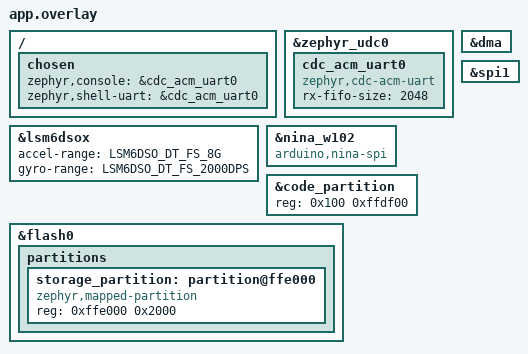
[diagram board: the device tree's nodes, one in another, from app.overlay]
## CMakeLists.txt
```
cmake_minimum_required(VERSION 3.28.0)
find_package(Zephyr REQUIRED HINTS $ENV{ZEPHYR_BASE})
project(usb_console)

target_sources(app PRIVATE src/main.c src/log_ram.c src/kv_store.c src/imu_cal.c src/imu_cal_codec.c src/wifi_profile.c
  src/time_sync.c src/time_offset.c
  src/imu_stream.c src/imu_raw_batch.c src/imu_raw_packet.c src/imu_raw_time.c
  src/imu_tick_clock.c src/imu_raw_queue.c src/imu_raw_mqtt.c src/imu_raw_status.c
  drivers/nina/nina_wifi.c drivers/nina/nina_net.c drivers/nina/nina_socket.c
  drivers/nina/nina_dns.c)
target_include_directories(app PRIVATE src drivers/lsm6dso)
# Keep Zephyr's Kconfig and devicetree bindings while using local driver copies.
function(use_local_driver_sources target pattern replacement_dir)
  get_target_property(sources ${target} SOURCES)
  set(updated_sources)
  set(replaced 0)
  foreach(source IN LISTS sources)
    if(source MATCHES "${pattern}")
      get_filename_component(filename "${source}" NAME)
      list(APPEND updated_sources "${CMAKE_CURRENT_SOURCE_DIR}/${replacement_dir}/${filename}")
      math(EXPR replaced "${replaced} + 1")
    else()
      list(APPEND updated_sources "${source}")
    endif()
  endforeach()
  if(replaced EQUAL 0)
    message(FATAL_ERROR "No sources replaced in ${target}; check the Zephyr version and configuration")
  endif()
  set_property(TARGET ${target} PROPERTY SOURCES "${updated_sources}")
endfunction()

use_local_driver_sources(drivers__i2c "(^|/)i2c_dw\\.c$" drivers/i2c_dw)
if(CONFIG_I2C_DW_RP2040_DMA)
  target_sources(drivers__i2c PRIVATE drivers/i2c_dw/i2c_dw_rp2040_commands.c)
endif()
target_include_directories(drivers__i2c PRIVATE "${ZEPHYR_BASE}/drivers/i2c")

use_local_driver_sources(drivers__sensor__st__lsm6dso "(^|/)lsm6dso(_shub|_trigger)?\\.c$" drivers/lsm6dso)
use_local_driver_sources(drivers__sensor "(^|/)sensor_shell\\.c$" drivers/sensor_shell)
target_include_directories(drivers__sensor PRIVATE ${ZEPHYR_BASE}/drivers/sensor)
target_sources(drivers__sensor__st__lsm6dso PRIVATE drivers/lsm6dso/lsm6dso_fifo.c)
target_sources(drivers__sensor__st__lsm6dso PRIVATE drivers/lsm6dso/lsm6dso_cal.c)
target_sources(drivers__sensor__st__lsm6dso PRIVATE drivers/lsm6dso/lsm6dso_zero.c)
target_sources(drivers__sensor__st__lsm6dso PRIVATE drivers/lsm6dso/lsm6dso_fifo_hw.c)
target_sources(drivers__sensor__st__lsm6dso PRIVATE drivers/lsm6dso/lsm6dso_fifo_irq.c)
if(CONFIG_SENSOR_ASYNC_API)
  target_sources(drivers__sensor__st__lsm6dso PRIVATE
    drivers/lsm6dso/lsm6dso_fifo_decoder.c
    drivers/lsm6dso/lsm6dso_compat.c
    drivers/lsm6dso/lsm6dso_stream.c)
endif()
```

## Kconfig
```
mainmenu "USB console"
source "Kconfig.zephyr"

config I2C_DW_RP2040_DMA
	bool "RP2040 I2C0 DMA reads"
	depends on SOC_RP2040 && I2C_DW && DMA_RPI_PICO && SHELL && !SMP
	depends on !I2C_DW_LPSS_DMA

config WIFI_NINA_LOCAL
	bool "NINA SPI Wi-Fi offload"
	default y
	select NET_L2_WIFI_MGMT
	select WIFI_OFFLOAD
	select NET_SOCKETS
	select NET_SOCKETS_OFFLOAD

config NINA_SPI_FREQUENCY
	int "NINA SPI frequency in Hz"
	default 8000000
	range 1000000 10000000
	depends on WIFI_NINA_LOCAL

config NINA_TCP_MAX_IO
	int "Maximum bytes per NINA TCP send"
	default 3584
	range 1 3584
	depends on WIFI_NINA_LOCAL
	help
	  Bounds each TCP send to leave room for framing in the NINA SPI
	  command buffer. A RAW batch of up to 2448 bytes plus its MQTT
	  header is sent in one command with the default.

config NINA_SEND_RETRY_MS
	int "Delay before retrying a full NINA TCP send buffer"
	default 1
	range 1 1000
	depends on WIFI_NINA_LOCAL

config NINA_NTP_SERVER
	string "NTP server hostname or IPv4 address"
	default ""
	depends on WIFI_NINA_LOCAL
	help
	  Empty uses the default gateway, normally the PC that provides the
	  Wi-Fi network and runs an NTP server for the board.

config NINA_NTP_PORT
	int "NTP server UDP port"
	default 123
	range 1 65535
	depends on WIFI_NINA_LOCAL

config NINA_NTP_INTERVAL_MS
	int "Interval between NTP queries in milliseconds"
	default 2000
	range 250 3600000
	depends on WIFI_NINA_LOCAL
	help
	  Queries go to a server on the local network. Do not point short
	  intervals at public servers.
```

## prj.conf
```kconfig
CONFIG_SERIAL=y
CONFIG_CONSOLE=y
CONFIG_UART_CONSOLE=y
CONFIG_UART_LINE_CTRL=y
CONFIG_SHELL=y
CONFIG_SHELL_HISTORY=y
CONFIG_SHELL_BACKEND_SERIAL_RX_RING_BUFFER_SIZE=2048
CONFIG_SHELL_CMD_BUFF_SIZE=512
CONFIG_SHELL_STACK_SIZE=3072
CONFIG_MAIN_STACK_SIZE=2048
CONFIG_GPIO=y
CONFIG_GPIO_SHELL=y
CONFIG_I2C=y
CONFIG_SPI=y
CONFIG_I2C_SHELL=y
CONFIG_I2C_SHELL_BUFFER_SIZE=64
CONFIG_SENSOR=y
CONFIG_SENSOR_SHELL=y
CONFIG_SENSOR_SHELL_STREAM=y
CONFIG_SENSOR_SHELL_THREAD_STACK_SIZE=3072
CONFIG_STACK_SENTINEL=y
CONFIG_POLL=y
CONFIG_LSM6DSO=y
CONFIG_REBOOT=y
# Reboot after a fatal error instead of halting; the report stays in the RAM log.
CONFIG_RESET_ON_FATAL_ERROR=y
CONFIG_THREAD_ANALYZER=y
CONFIG_THREAD_ANALYZER_USE_PRINTK=y
CONFIG_LOG=y
CONFIG_LOG_OUTPUT=y
CONFIG_LOG_TIMESTAMP_64BIT=y
CONFIG_LOG_CMDS=y
CONFIG_LOG_RUNTIME_FILTERING=y
CONFIG_SHELL_LOG_BACKEND=n
CONFIG_LOG_BACKEND_UART=n

CONFIG_USB_DEVICE_STACK_NEXT=y
CONFIG_USBD_CDC_ACM_LOG_LEVEL_OFF=y
CONFIG_CDC_ACM_SERIAL_INITIALIZE_AT_BOOT=y
CONFIG_CDC_ACM_SERIAL_PID=0x0004
CONFIG_CDC_ACM_SERIAL_PRODUCT_STRING="Zephyr USB Console"

# Measure active time from CPU idle windows, including interrupts.
CONFIG_CPU_LOAD=y
CONFIG_CPU_LOAD_BACKEND_IDLE_HOOK=y

# Use DMA for eligible I2C0 reads.
CONFIG_DMA=y
CONFIG_I2C_DW_RP2040_DMA=y

# NINA Wi-Fi management and socket offload.
CONFIG_NETWORKING=y
CONFIG_WIFI=y
CONFIG_WIFI_CREDENTIALS=y
CONFIG_WIFI_CREDENTIALS_BACKEND_SETTINGS=y
CONFIG_WIFI_NINA_LOCAL=y
CONFIG_NET_IPV4=y
CONFIG_NET_TCP=y
CONFIG_SHELL_BACKEND_TELNET=y
CONFIG_ZVFS_POLL_MAX=16
CONFIG_NET_ZPERF=y
CONFIG_NET_ZPERF_IPERF3=y
CONFIG_NET_ZPERF_SERVER=y
CONFIG_NET_L2_WIFI_SHELL=y
CONFIG_NET_SHELL=y
CONFIG_MQTT_LIB=y
# Network event callbacks may print Wi-Fi results through the shell. Measured
# peak use is 924 bytes including a Wi-Fi scan.
CONFIG_NET_MGMT_EVENT_STACK_SIZE=2048
# Every socket is offloaded to the NINA, so Zephyr's own IP stack carries no
# traffic ("net conn" stays empty). Keep its packet buffers and connection
# tables at a minimum instead of the defaults sized for native networking.
CONFIG_NET_PKT_RX_COUNT=2
CONFIG_NET_PKT_TX_COUNT=2
CONFIG_NET_BUF_RX_COUNT=4
CONFIG_NET_BUF_TX_COUNT=4
CONFIG_NET_MAX_CONTEXTS=2
CONFIG_NET_MAX_CONN=2
# Zephyr derives the size of the file descriptor table from NET_MAX_CONTEXTS,
# which no longer reflects the sockets in use. Size it for the ten NINA
# sockets, stdin/stdout/stderr and the socket service's eventfd. With too few,
# accepting a Telnet client fails in a tight loop.
CONFIG_ZVFS_OPEN_MAX=16
CONFIG_WIFI_ESP_AT=n
# Temporary non-cryptographic random generator for network testing; no TLS.
CONFIG_TEST_RANDOM_GENERATOR=y
CONFIG_NET_IPV6=n

# Persist the most recently successful Wi-Fi connection.
CONFIG_FLASH=y
CONFIG_FLASH_MAP=y
CONFIG_NVS=y
CONFIG_SETTINGS=y
CONFIG_SETTINGS_NVS=y

# Identifies the board in automatically assigned IMU session IDs.
CONFIG_HWINFO=y
```

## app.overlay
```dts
#include <zephyr/dt-bindings/sensor/lsm6dso.h>

/ {
	chosen {
		zephyr,console = &cdc_acm_uart0;
		zephyr,shell-uart = &cdc_acm_uart0;
	};
};

&zephyr_udc0 {
	cdc_acm_uart0: cdc_acm_uart0 {
		compatible = "zephyr,cdc-acm-uart";
		rx-fifo-size = <2048>;
	};
};

&dma {
	status = "okay";
};

&spi1 {
	status = "okay";
};

/* Wide ranges: the noise at 6667 Hz is well above one LSB even here, and a
 * saturated gyro sample cannot be recovered afterwards.
 */
&lsm6dsox {
	accel-range = <LSM6DSO_DT_FS_8G>;
	gyro-range = <LSM6DSO_DT_FS_2000DPS>;
};

&nina_w102 {
	compatible = "arduino,nina-spi";
};

/* Reserve the last two erase sectors for settings; keep the image separate. */
&code_partition {
	reg = <0x100 0xffdf00>;
};

&flash0 {
	partitions {
		storage_partition: partition@ffe000 {
			compatible = "zephyr,mapped-partition";
			reg = <0xffe000 0x2000>;
		};
	};
};
```

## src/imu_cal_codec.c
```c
/* SPDX-License-Identifier: Apache-2.0 */

#include <errno.h>
#include <stdio.h>
#include "imu_cal.h"

static uint32_t get_le32(const uint8_t *p)
{
	return (uint32_t)p[0] | (uint32_t)p[1] << 8 | (uint32_t)p[2] << 16 | (uint32_t)p[3] << 24;
}

int imu_cal_key(enum lsm6dso_cal_kind kind, uint32_t gain, char *key, size_t capacity)
{
	int len = snprintf(key, capacity, "imu.cal.%s.%u",
			   kind == LSM6DSO_CAL_ACCEL ? "accel" : "gyro", (unsigned int)gain);

	return len < 0 || (size_t)len >= capacity ? -ENAMETOOLONG : len;
}

int imu_cal_decode(const uint8_t *blob, size_t len, enum lsm6dso_cal_kind kind, uint32_t gain,
		   struct lsm6dso_cal *cal)
{
	if (len != IMU_CAL_BLOB_SIZE || blob[0] != IMU_CAL_VERSION || blob[2] != 0 || blob[3] != 0) {
		return -EINVAL;
	}
	if (blob[1] != (kind == LSM6DSO_CAL_ACCEL ? 0 : 1) || get_le32(blob + 4) != gain) {
		return -ENOENT;
	}
	for (int i = 0; i < 9; i++) {
		cal->m[i / 3][i % 3] = (int32_t)get_le32(blob + 8 + 4 * i);
	}
	for (int i = 0; i < 3; i++) {
		cal->bias[i] = (int32_t)get_le32(blob + 44 + 4 * i);
	}
	return 0;
}
```

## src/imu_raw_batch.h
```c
/* SPDX-License-Identifier: Apache-2.0 */
#ifndef IMU_RAW_BATCH_H_
#define IMU_RAW_BATCH_H_

#include "imu_raw_packet.h"
#include "imu_raw_time.h"

/* Runs in the FIFO consumer. The sink must not wait or retain payload; it
 * returns 0 after copying or -EAGAIN if it cannot accept the batch. */
typedef int (*imu_raw_batch_sink)(void *context, const uint8_t *payload, size_t length);
/* Optional: server (Unix) time in microseconds for a sensor tick. Called at
 * most twice per batch with ticks that never decrease. Must not wait long. */
typedef bool (*imu_raw_batch_clock)(void *context, uint64_t tick, uint64_t *unix_us);

struct imu_raw_batch {
	struct imu_raw_metadata meta;
	uint8_t payload[IMU_RAW_MAX_SIZE]; /* built in place, see imu_raw_stage_put() */
	uint64_t next_accel, next_gyro, next_batch;
	uint64_t delivered_batches, dropped_batches, dropped_accel, dropped_gyro;
	uint64_t timestamp_words;
	struct imu_raw_time time;
	size_t count, accel_count; /* words in the batch being built */
	/* A first tick was noted and awaits confirmation; see imu_raw_time.h. */
	bool accel_tick_noted, gyro_tick_noted;
	uint32_t accel_tick_generation, gyro_tick_generation;
	uint64_t accel_noted_tick, gyro_noted_tick;
	imu_raw_batch_sink sink;
	void *sink_context;
	imu_raw_batch_clock clock; /* set after init; NULL leaves Unix time invalid */
	void *clock_context;
};

/* The caller supplies a unique session ID; no random ID is generated here. */
int imu_raw_batch_init(struct imu_raw_batch *batch, const uint8_t session_id[16],
		       uint32_t epoch_id, imu_raw_batch_sink sink, void *context);
/* cursor is a byte offset into a FIFO word array. Each valid sample is
 * numbered before the sink is called. The first accelerometer and gyroscope
 * sample of a batch carry their sensor tick when imu_raw_time can assign one
 * and has confirmed it by the time the batch is flushed; otherwise the
 * time-valid flag stays clear.
 * Unsupported tags return -EPROTO without consuming the offending word.
 */
int imu_raw_batch_consume(struct imu_raw_batch *batch, const uint8_t *words,
			  size_t length, size_t *cursor);
/* Flush the incomplete batch at a deadline, stop, or before an epoch change. */
int imu_raw_batch_flush(struct imu_raw_batch *batch);
/* Call after an unknown number of samples was lost (FIFO overrun, restart,
 * unparsable word). Flushes what was collected and starts the next epoch.
 * Batch and sample numbers keep counting so they stay unique in the session;
 * consecutive numbers on both sides of an epoch change do not mean that the
 * samples are contiguous. On a flush error the epoch is left unchanged.
 */
int imu_raw_batch_new_epoch(struct imu_raw_batch *batch);
#endif
```

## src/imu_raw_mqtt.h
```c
/* SPDX-License-Identifier: Apache-2.0 */
#ifndef IMU_RAW_MQTT_H_
#define IMU_RAW_MQTT_H_
#include <stdbool.h>
#include <stddef.h>
#include <stdint.h>
#include <zephyr/net/net_ip.h>
#include "imu_raw_status.h"

/* MQTT transport for RAW batches (QoS 0), info and status. It owns a bounded
 * queue: batches are dropped and counted while disconnected or when the
 * queue is full, never retried. Thread context only. */
#define IMU_RAW_MQTT_DEVICE_ID_MAX 40

struct imu_raw_mqtt_config {
	/* 0.0.0.0 means the default gateway, looked up again for every
	 * connection attempt: the session then follows the network the board
	 * is on, and can be started before Wi-Fi is connected. */
	struct in_addr address;
	uint16_t port;
	/* Letters, digits, '-' and '_'; used in topics and the client ID. */
	char device_id[IMU_RAW_MQTT_DEVICE_ID_MAX + 1];
	uint8_t session_id[16];
};

struct imu_raw_mqtt_stats {
	bool running, connected;
	bool via_gateway;       /* no fixed address configured */
	struct in_addr address; /* of the latest connection attempt; 0 if none */
	uint16_t port;
	size_t queued, queue_high;
	uint32_t published; /* accepted by the socket, not confirmed delivered */
	uint32_t failures, connects, status_published, info_published;
	uint64_t dropped_batches, dropped_accel, dropped_gyro;
	uint64_t lock_wait_count, lock_wait_total_us, lock_wait_max_us;
	uint64_t publish_total_us, publish_max_us, publish_bytes;
};

/* -EBUSY while a previous session is still shutting down, -EINVAL for a bad
 * device ID or port. Counters restart. */
int imu_raw_mqtt_start(const struct imu_raw_mqtt_config *config);
/* Gives a final status up to half a second to leave, then disconnects. */
void imu_raw_mqtt_stop(void);
/* Sink for imu_raw_batch. May wait for the queue mutex; never waits on the
 * network. Returns -EAGAIN for a batch that was dropped. */
int imu_raw_mqtt_submit(void *context, const uint8_t *payload, size_t length);
/* Neither waits on the network. Info is published on every (re)connection and
 * when it changes; status periodically, on (re)connection and when the state
 * changes. Only the acquisition fields of *status are used. Nothing is kept
 * for a disconnected period. */
void imu_raw_mqtt_set_info(const struct imu_raw_info *info);
void imu_raw_mqtt_report(const struct imu_raw_status *status);
void imu_raw_mqtt_get_stats(struct imu_raw_mqtt_stats *stats);
#endif
```

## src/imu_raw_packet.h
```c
/* SPDX-License-Identifier: Apache-2.0 */
#ifndef IMU_RAW_PACKET_H_
#define IMU_RAW_PACKET_H_

#include <stddef.h>
#include <stdint.h>
#include "../drivers/lsm6dso/lsm6dso_fifo.h"

/* Experimental payload based on design/imu-raw-mqtt-design-ja.md §6.
 * Version 2 appends the server (Unix) time of the first sample of each kind
 * to the version 1 header:
 *   80  u64  accel_first_unix_us
 *   88  u64  gyro_first_unix_us
 * and uses flag bits 2 and 3 for their validity. Everything before offset 80
 * is laid out as in version 1.
 */
#define IMU_RAW_VERSION 2U
#define IMU_RAW_HEADER_SIZE 96U
#define IMU_RAW_MAX_WORDS 384U
#define IMU_RAW_MAX_BITMAP ((IMU_RAW_MAX_WORDS + 7U) / 8U)
#define IMU_RAW_MAX_SIZE (IMU_RAW_HEADER_SIZE + IMU_RAW_MAX_BITMAP + 6U * IMU_RAW_MAX_WORDS)
#define IMU_RAW_ACCEL_TIME_VALID 1U
#define IMU_RAW_GYRO_TIME_VALID 2U
#define IMU_RAW_ACCEL_UNIX_VALID 4U
#define IMU_RAW_GYRO_UNIX_VALID 8U
#define IMU_RAW_FLAGS_MASK 15U

struct imu_raw_metadata {
	uint8_t session_id[16];
	uint64_t batch_seq;
	uint64_t accel_first_index, gyro_first_index;
	uint64_t accel_first_tick, gyro_first_tick;
	/* Microseconds since 1970 as estimated by the board when the batch was
	 * built. Derived from the tick, so it needs the tick to be valid. */
	uint64_t accel_first_unix_us, gyro_first_unix_us;
	uint32_t epoch_id, time_map_id;
	uint8_t flags;
};

/* Encodes one complete payload. The caller owns numbering, timing, and transport.
 * An absent sensor must have index UINT64_MAX and tick 0; invalid time has tick 0
 * and an invalid Unix time is 0.
 * On error, *written is set to zero and no output bytes are changed.
 */
int imu_raw_encode(uint8_t *out, size_t capacity, size_t *written,
		   const struct imu_raw_metadata *meta,
		   const struct lsm6dso_fifo_sample *samples, size_t count);

/* The same payload built one word at a time in a buffer of IMU_RAW_MAX_SIZE
 * bytes, so that the samples need not be kept elsewhere first:
 *   imu_raw_stage_reset(), then imu_raw_stage_put() for words 0, 1, 2, ...,
 *   then imu_raw_stage_finish(), which leaves the complete payload in place.
 * `accel` is the number of accelerometer words among the `count` put.
 * After finish the buffer must be reset before the next payload, or reopened
 * with the same count to continue adding to this one. An error from finish
 * leaves the staged words untouched.
 */
void imu_raw_stage_reset(uint8_t *payload);
void imu_raw_stage_put(uint8_t *payload, size_t index, const struct lsm6dso_fifo_sample *sample);
int imu_raw_stage_finish(uint8_t *payload, size_t *written, const struct imu_raw_metadata *meta,
			 size_t count, size_t accel);
void imu_raw_stage_reopen(uint8_t *payload, size_t count);
#endif
```

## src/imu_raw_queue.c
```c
/* SPDX-License-Identifier: Apache-2.0 */
#include "imu_raw_queue.h"

#include <errno.h>
#include <string.h>

static uint16_t le16(const uint8_t *p)
{
	return (uint16_t)p[0] | ((uint16_t)p[1] << 8);
}

void imu_raw_queue_init(struct imu_raw_queue *queue)
{
	if (queue) {
		memset(queue, 0, sizeof(*queue));
	}
}

void imu_raw_queue_discard(struct imu_raw_queue *queue, const struct imu_raw_queue_item *item)
{
	if (!queue || !item) {
		return;
	}
	queue->dropped_batches++;
	queue->dropped_accel += item->accel_count;
	queue->dropped_gyro += item->gyro_count;
}

void imu_raw_queue_set_connected(struct imu_raw_queue *queue, bool connected)
{
	if (!queue) {
		return;
	}
	queue->connected = connected;
	if (!connected) {
		while (queue->count) {
			imu_raw_queue_discard(queue, &queue->items[queue->head]);
			queue->head = (queue->head + 1) % IMU_RAW_QUEUE_CAPACITY;
			queue->count--;
		}
	}
}

int imu_raw_queue_put(struct imu_raw_queue *queue, const uint8_t *payload, size_t length)
{
	struct imu_raw_queue_item *item;
	uint16_t count, bitmap, accel = 0;

	if (!queue || !payload || length < IMU_RAW_HEADER_SIZE ||
	    memcmp(payload, "IMU1", 4) || payload[4] != IMU_RAW_VERSION ||
	    le16(payload + 6) != IMU_RAW_HEADER_SIZE) {
		return -EINVAL;
	}
	count = le16(payload + 64);
	bitmap = le16(payload + 66);
	if (!count || count > IMU_RAW_MAX_WORDS || bitmap != (count + 7) / 8 ||
	    length != IMU_RAW_HEADER_SIZE + bitmap + (size_t)count * 6) {
		return -EINVAL;
	}
	for (size_t i = 0; i < count; i++) {
		accel += (payload[IMU_RAW_HEADER_SIZE + i / 8] >> (i % 8)) & 1U;
	}
	if (!queue->connected || queue->count == IMU_RAW_QUEUE_CAPACITY) {
		queue->dropped_batches++;
		queue->dropped_accel += accel;
		queue->dropped_gyro += count - accel;
		return -EAGAIN;
	}
	item = &queue->items[(queue->head + queue->count) % IMU_RAW_QUEUE_CAPACITY];
	item->length = length;
	item->accel_count = accel;
	item->gyro_count = count - accel;
	memcpy(item->payload, payload, length);
	queue->count++;
	if (queue->count > queue->high_watermark) {
		queue->high_watermark = queue->count;
	}
	return 0;
}

int imu_raw_queue_take(struct imu_raw_queue *queue, struct imu_raw_queue_item *item)
{
	if (!queue || !item) {
		return -EINVAL;
	}
	if (!queue->connected || !queue->count) {
		return -EAGAIN;
	}
	*item = queue->items[queue->head];
	queue->head = (queue->head + 1) % IMU_RAW_QUEUE_CAPACITY;
	queue->count--;
	return 0;
}
```

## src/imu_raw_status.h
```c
/* SPDX-License-Identifier: Apache-2.0 */
#ifndef IMU_RAW_STATUS_H_
#define IMU_RAW_STATUS_H_

#include <stdbool.h>
#include <stddef.h>
#include <stdint.h>

/* Experimental JSON for imu/<device_id>/status and imu/<device_id>/info
 * (design/imu-raw-mqtt-design-ja.md §5). Batch ticks are in the sensor's own
 * clock; conversion to host time is not implemented and status says so. */
enum imu_raw_state {
	IMU_RAW_STATE_IDLE,      /* session configured, no measurement yet */
	IMU_RAW_STATE_MEASURING,
	IMU_RAW_STATE_STOPPED,
};

struct imu_raw_status {
	/* Filled by the acquisition side. Numbers advance whether or not a
	 * batch was sent, so they are the reference for detecting loss. */
	uint8_t session_id[16];
	enum imu_raw_state state;
	uint32_t epoch_id;
	uint64_t uptime_ms;
	uint64_t accel_acquired, gyro_acquired, next_batch, timestamp_words;
	uint32_t fifo_overrun_observations, i2c_errors;
	int raw_error, measure_error;
	/* One reading of the sensor's tick counter and the board clock taken
	 * together, with the board's estimate of server (Unix) time for that
	 * instant. The receiver relates batch ticks to its own time from a
	 * series of these; the board does not convert sample times itself. */
	bool tick_valid, unix_valid;
	uint64_t tick;              /* extended like the batch ticks */
	int64_t tick_mono_us;       /* board clock at the middle of the read */
	uint32_t tick_window_us;    /* duration of the read */
	int64_t unix_us;            /* smoothed: strictly increasing */
	int64_t unix_estimate_us;   /* unsmoothed: may jump either way */
	uint32_t sync_delay_us;     /* round trip behind the estimate */
	/* Filled by the transport. */
	uint64_t dropped_batches, dropped_accel, dropped_gyro, published;
	uint32_t connects, failures, queue_high_watermark;
};

struct imu_raw_info {
	uint8_t session_id[16];
	uint32_t epoch_id;
	uint16_t accel_odr_hz, gyro_odr_hz; /* configured, not measured */
	uint32_t accel_ug_per_lsb, gyro_udps_per_lsb;
	uint16_t fifo_watermark;
	uint8_t timestamp_decimation;
	/* Sensor clock: one tick is 1 / (40000 * (1 + 0.0015 * freq_fine)) s per
	 * the LSM6DSO datasheet. Not related to host time. */
	int8_t freq_fine;
};

/* Both return the JSON length (without a terminator being counted) or
 * -ENOSPC/-EINVAL. The output is always NUL-terminated on success. */
int imu_raw_status_encode(char *out, size_t capacity, const struct imu_raw_status *status);
int imu_raw_info_encode(char *out, size_t capacity, const struct imu_raw_info *info,
			const char *device_id);
#endif
```

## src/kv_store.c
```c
/* SPDX-License-Identifier: Apache-2.0 */
#include <errno.h>
#include <string.h>
#include <zephyr/settings/settings.h>
#include <zephyr/shell/shell.h>
#include <zephyr/sys/util.h>
#include "kv_store.h"

#define KV_PREFIX        "app_kv/"
#define KV_SYSTEM_PREFIX "sys."

static bool shell_key_allowed(const char *key)
{
	return strncmp(key, KV_SYSTEM_PREFIX, sizeof(KV_SYSTEM_PREFIX) - 1) !=
	       0;
}

static int make_name(const char *key, char *name, size_t capacity)
{
	size_t len;

	if (!key) {
		return -EINVAL;
	}
	len = strnlen(key, KV_STORE_KEY_MAX + 1);
	if (!len || len > KV_STORE_KEY_MAX) {
		return -EINVAL;
	}
	for (size_t i = 0; i < len; i++) {
		char c = key[i];

		if (!((c >= 'a' && c <= 'z') || (c >= 'A' && c <= 'Z') ||
		      (c >= '0' && c <= '9') || c == '_' || c == '-' ||
		      c == '.')) {
			return -EINVAL;
		}
	}
	if (sizeof(KV_PREFIX) + len > capacity) {
		return -ENAMETOOLONG;
	}
	memcpy(name, KV_PREFIX, sizeof(KV_PREFIX) - 1);
	memcpy(name + sizeof(KV_PREFIX) - 1, key, len + 1);
	return 0;
}

int kv_store_init(void)
{
	return settings_subsys_init();
}

int kv_store_set(const char *key, const void *value, size_t len)
{
	char name[sizeof(KV_PREFIX) + KV_STORE_KEY_MAX];
	int ret = make_name(key, name, sizeof(name));

	if (ret) {
		return ret;
	}
	if (!value || !len || len > KV_STORE_VALUE_MAX) {
		return -EINVAL;
	}
	ret = kv_store_init();
	if (ret) {
		return ret;
	}
	return settings_save_one(name, value, len);
}

ssize_t kv_store_get(const char *key, void *value, size_t capacity)
{
	char name[sizeof(KV_PREFIX) + KV_STORE_KEY_MAX];
	ssize_t len;
	int ret = make_name(key, name, sizeof(name));

	if (ret) {
		return ret;
	}
	if (!value || !capacity) {
		return -EINVAL;
	}
	ret = kv_store_init();
	if (ret) {
		return ret;
	}
	len = settings_load_one(name, value, capacity);
	if (len == 0) {
		return -ENOENT;
	}
	if (len > 0 && (size_t)len > capacity) {
		return -ENOBUFS;
	}
	return len;
}

int kv_store_delete(const char *key)
{
	char name[sizeof(KV_PREFIX) + KV_STORE_KEY_MAX];
	int ret = make_name(key, name, sizeof(name));

	if (ret) {
		return ret;
	}
	ret = kv_store_init();
	return ret ? ret : settings_delete(name);
}

static int cmd_set(const struct shell *sh, size_t argc, char **argv)
{
	int ret;

	ARG_UNUSED(argc);
	if (!shell_key_allowed(argv[1])) {
		shell_error(sh, "Reserved key");
		return -EACCES;
	}
	ret = kv_store_set(argv[1], argv[2], strlen(argv[2]));
	if (ret) {
		shell_error(sh, "KV write failed: %d", ret);
	} else {
		shell_print(sh, "Saved");
	}
	return ret;
}

static int cmd_sethex(const struct shell *sh, size_t argc, char **argv)
{
	uint8_t value[KV_STORE_VALUE_MAX];
	size_t chars = strlen(argv[2]);
	size_t len;
	int ret;

	ARG_UNUSED(argc);
	if (!shell_key_allowed(argv[1])) {
		shell_error(sh, "Reserved key");
		return -EACCES;
	}
	if (!chars || chars % 2 || chars > sizeof(value) * 2) {
		shell_error(sh, "Expected 1-128 bytes as hexadecimal pairs");
		return -EINVAL;
	}
	len = hex2bin(argv[2], chars, value, sizeof(value));
	if (len != chars / 2) {
		shell_error(sh, "Invalid hexadecimal value");
		return -EINVAL;
	}
	ret = kv_store_set(argv[1], value, len);
	if (ret) {
		shell_error(sh, "KV write failed: %d", ret);
	} else {
		shell_print(sh, "Saved");
	}
	return ret;
}

static int cmd_get(const struct shell *sh, size_t argc, char **argv)
{
	uint8_t value[KV_STORE_VALUE_MAX];
	char hex[2 * KV_STORE_VALUE_MAX + 1];
	ssize_t len;

	ARG_UNUSED(argc);
	if (!shell_key_allowed(argv[1])) {
		shell_error(sh, "Reserved key");
		return -EACCES;
	}
	len = kv_store_get(argv[1], value, sizeof(value));
	if (len < 0) {
		shell_error(sh, "KV read failed: %d", (int)len);
		return (int)len;
	}
	bin2hex(value, len, hex, sizeof(hex));
	shell_print(sh, "%s", hex);
	return 0;
}

static int cmd_delete(const struct shell *sh, size_t argc, char **argv)
{
	int ret;

	ARG_UNUSED(argc);
	if (!shell_key_allowed(argv[1])) {
		shell_error(sh, "Reserved key");
		return -EACCES;
	}
	ret = kv_store_delete(argv[1]);
	if (ret) {
		shell_error(sh, "KV delete failed: %d", ret);
	} else {
		shell_print(sh, "Deleted");
	}
	return ret;
}

SHELL_STATIC_SUBCMD_SET_CREATE(
	kv_commands,
	SHELL_CMD_ARG(set, NULL, "Store a text value: <key> <value>", cmd_set,
		      3, 0),
	SHELL_CMD_ARG(sethex, NULL, "Store hex bytes: <key> <hex>", cmd_sethex,
		      3, 0),
	SHELL_CMD_ARG(get, NULL, "Print a value as hex: <key>", cmd_get, 2, 0),
	SHELL_CMD_ARG(delete, NULL, "Delete a value: <key>", cmd_delete, 2, 0),
	SHELL_SUBCMD_SET_END);
SHELL_CMD_REGISTER(kv, &kv_commands, "Application key-value storage", NULL);
```

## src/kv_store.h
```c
/* SPDX-License-Identifier: Apache-2.0 */
#ifndef APP_KV_STORE_H_
#define APP_KV_STORE_H_

#include <stddef.h>
#include <sys/types.h>

#define KV_STORE_KEY_MAX   32
#define KV_STORE_VALUE_MAX 128

/* Keys contain ASCII letters, digits, '.', '-' or '_'. Values are binary.
 * A zero-length value is not supported. Data is stored without encryption.
 * All calls must run in thread context and return negative errno on failure.
 */
int kv_store_init(void);
int kv_store_set(const char *key, const void *value, size_t len);
/* Returns the value length; -ENOENT if absent, -ENOBUFS if too small. */
ssize_t kv_store_get(const char *key, void *value, size_t capacity);
int kv_store_delete(const char *key);

#endif
```

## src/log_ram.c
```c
#include <zephyr/kernel.h>
#include <zephyr/linker/section_tags.h>
#include <zephyr/logging/log_backend.h>
#include <zephyr/logging/log_ctrl.h>
#include <zephyr/logging/log_msg.h>
#include <zephyr/logging/log_output.h>
#include <zephyr/shell/shell.h>

#define LOG_RAM_SIZE 4096
#define LOG_RAM_MAGIC 0x4c4f4752U

struct retained_log {
	uint32_t magic;
	uint32_t magic_inverse;
	size_t start;
	size_t length;
	char buffer[LOG_RAM_SIZE];
};

/* The linker leaves this region untouched during normal startup. */
static __noinit struct retained_log retained;
/* Bytes pushed out of the buffer since boot. Protected by log_lock. */
static uint64_t dropped;
static struct k_spinlock log_lock;
static uint8_t format_buffer[128];

static int store_output(uint8_t *data, size_t length, void *ctx)
{
	k_spinlock_key_t key;

	ARG_UNUSED(ctx);
	key = k_spin_lock(&log_lock);
	for (size_t i = 0; i < length; i++) {
		if (retained.length == LOG_RAM_SIZE) {
			retained.start = (retained.start + 1) % LOG_RAM_SIZE;
			retained.length--;
			dropped++;
		}
		retained.buffer[(retained.start + retained.length) % LOG_RAM_SIZE] = data[i];
		retained.length++;
	}
	k_spin_unlock(&log_lock, key);
	return (int)length;
}

LOG_OUTPUT_DEFINE(ram_output, store_output, format_buffer, sizeof(format_buffer));

static void ram_process(const struct log_backend *const backend, union log_msg_generic *msg)
{
	ARG_UNUSED(backend);
	log_output_msg_process(&ram_output, &msg->log,
			       LOG_OUTPUT_FLAG_TIMESTAMP | LOG_OUTPUT_FLAG_FORMAT_TIMESTAMP |
			       LOG_OUTPUT_FLAG_LEVEL | LOG_OUTPUT_FLAG_CRLF_LFONLY);
}

static void ram_panic(const struct log_backend *const backend)
{
	ARG_UNUSED(backend);
}

static log_timestamp_t timestamp_us(void)
{
	return k_cyc_to_us_floor64(k_cycle_get_64());
}

static void ram_init(const struct log_backend *const backend)
{
	ARG_UNUSED(backend);
	log_set_timestamp_func(timestamp_us, 1000000U);
	if (retained.magic != LOG_RAM_MAGIC || retained.magic_inverse != ~LOG_RAM_MAGIC ||
	    retained.start >= LOG_RAM_SIZE || retained.length > LOG_RAM_SIZE) {
		retained.start = 0;
		retained.length = 0;
		retained.magic_inverse = ~LOG_RAM_MAGIC;
		retained.magic = LOG_RAM_MAGIC;
	}
}

static const struct log_backend_api ram_backend_api = {
	.process = ram_process,
	.panic = ram_panic,
	.init = ram_init,
};

LOG_BACKEND_DEFINE(ram_backend, ram_backend_api, true);

/* Prints the log in pieces so that no second copy of it is needed. `dropped`
 * numbers the bytes from boot, which keeps the position valid when new
 * messages push old ones out while printing. */
static int cmd_dmesg(const struct shell *sh, size_t argc, char **argv)
{
	char piece[97];
	uint64_t position = 0;
	bool first = true, any = false;

	ARG_UNUSED(argc);
	ARG_UNUSED(argv);
	/* Bounded in case logging keeps up with printing. */
	for (size_t printed = 0; printed < 2U * LOG_RAM_SIZE;) {
		k_spinlock_key_t key = k_spin_lock(&log_lock);
		size_t available, n;

		if (first || position < dropped) {
			position = dropped; /* start, or skip what was overwritten */
			first = false;
		}
		available = (size_t)(dropped + retained.length - position);
		n = MIN(available, sizeof(piece) - 1);
		for (size_t k = 0; k < n; k++) {
			piece[k] = retained.buffer[(retained.start + (size_t)(position - dropped) + k) %
						   LOG_RAM_SIZE];
		}
		k_spin_unlock(&log_lock, key);
		if (!n) {
			break;
		}
		piece[n] = '\0';
		shell_fprintf(sh, SHELL_NORMAL, "%s", piece);
		position += n;
		printed += n;
		any = true;
	}
	if (!any) {
		shell_print(sh, "No logs.");
	}
	return 0;
}

SHELL_CMD_REGISTER(dmesg, NULL, "Show logs stored in RAM", cmd_dmesg);
```

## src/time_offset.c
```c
/* SPDX-License-Identifier: Apache-2.0 */
#include "time_offset.h"

#include <string.h>

void time_offset_init(struct time_offset *t)
{
	memset(t, 0, sizeof(*t));
	t->min_delay_us = UINT32_MAX;
}

static const struct time_offset_sample *best(const struct time_offset *t)
{
	const struct time_offset_sample *b = NULL;

	for (unsigned int i = 0; i < t->count; i++) {
		if (!b || t->window[i].delay_us < b->delay_us) {
			b = &t->window[i];
		}
	}
	return b;
}

bool time_offset_get(const struct time_offset *t, int64_t mono_us, int64_t *server_us,
		     uint32_t *delay_us)
{
	const struct time_offset_sample *b = best(t);
	int64_t offset;

	if (!b) {
		return false;
	}
	offset = b->offset_us;
	if (t->rate_valid) {
		offset += (mono_us - b->mono_us) * t->rate_ppb / 1000000000LL;
	}
	*server_us = mono_us + offset;
	if (delay_us) {
		*delay_us = b->delay_us;
	}
	return true;
}

static void update_rate(struct time_offset *t)
{
	const struct time_offset_sample *first = &t->anchors[0];
	const struct time_offset_sample *last = &t->anchors[t->anchor_count - 1];
	int64_t span = last->mono_us - first->mono_us;
	int64_t rate;

	if (t->anchor_count < 2 || span < TIME_OFFSET_MIN_RATE_SPAN_US) {
		return;
	}
	rate = (last->offset_us - first->offset_us) * 1000000000LL / span;
	if (rate > TIME_OFFSET_MAX_RATE_PPB || rate < -TIME_OFFSET_MAX_RATE_PPB) {
		/* Not a plausible oscillator difference: a clock was stepped or
		 * the path changed. Start over from the newest point. */
		t->anchors[0] = *last;
		t->anchor_count = 1;
		t->rate_valid = false;
		return;
	}
	t->rate_ppb = rate;
	t->rate_valid = true;
}

void time_offset_add(struct time_offset *t, const struct time_offset_sample *sample)
{
	int64_t predicted;

	t->last_residual_us = time_offset_get(t, sample->mono_us, &predicted, NULL) ?
		sample->mono_us + sample->offset_us - predicted : 0;
	t->window[t->next] = *sample;
	t->next = (t->next + 1) % TIME_OFFSET_WINDOW;
	if (t->count < TIME_OFFSET_WINDOW) {
		t->count++;
	}
	t->samples++;
	t->last_delay_us = sample->delay_us;
	if (sample->delay_us < t->min_delay_us) {
		t->min_delay_us = sample->delay_us;
	}
	/* Once per full window, keep its best exchange for the rate. */
	if (++t->since_anchor == TIME_OFFSET_WINDOW) {
		t->since_anchor = 0;
		if (t->anchor_count == TIME_OFFSET_ANCHORS) {
			memmove(&t->anchors[0], &t->anchors[1],
				(TIME_OFFSET_ANCHORS - 1) * sizeof(t->anchors[0]));
			t->anchor_count--;
		}
		t->anchors[t->anchor_count++] = *best(t);
		update_rate(t);
	}
}

void time_slew_init(struct time_slew *s)
{
	memset(s, 0, sizeof(*s));
}

static int64_t segment_time(const struct time_slew_segment *g, int64_t mono_us)
{
	int64_t elapsed = mono_us - g->ref_mono_us;
	/* The correction ends after TIME_SLEW_SPAN_US even if no update follows,
	 * so a lost server cannot make the clock run away. */
	int64_t slewing = elapsed < TIME_SLEW_SPAN_US ? elapsed : TIME_SLEW_SPAN_US;

	return g->ref_time_us + elapsed + elapsed * g->rate_ppb / 1000000000LL +
	       slewing * g->slew_ppb / 1000000000LL;
}

bool time_slew_get(const struct time_slew *s, int64_t mono_us, int64_t *time_us)
{
	if (!s->valid) {
		return false;
	}
	if (mono_us >= s->now.ref_mono_us) {
		*time_us = segment_time(&s->now, mono_us);
		return true;
	}
	if (s->previous_valid && mono_us >= s->previous.ref_mono_us) {
		*time_us = segment_time(&s->previous, mono_us);
		return true;
	}
	return false;
}

void time_slew_update(struct time_slew *s, int64_t mono_us, int64_t target_us, int64_t rate_ppb)
{
	int64_t current, error, slew;

	if (!s->valid || mono_us < s->now.ref_mono_us) {
		s->previous_valid = false;
		s->now = (struct time_slew_segment){mono_us, target_us, rate_ppb, 0};
		if (s->valid) {
			s->steps++;
		}
		s->valid = true;
		return;
	}
	current = segment_time(&s->now, mono_us);
	error = target_us - current;
	if (error >= TIME_SLEW_STEP_US || error <= -TIME_SLEW_STEP_US) {
		/* Times before a step must not be converted with the new clock. */
		s->previous_valid = false;
		s->now = (struct time_slew_segment){mono_us, target_us, rate_ppb, 0};
		s->steps++;
		return;
	}
	slew = error * 1000000000LL / TIME_SLEW_SPAN_US;
	if (slew > TIME_SLEW_MAX_PPB) {
		slew = TIME_SLEW_MAX_PPB;
	} else if (slew < -TIME_SLEW_MAX_PPB) {
		slew = -TIME_SLEW_MAX_PPB;
	}
	s->previous = s->now;
	s->previous_valid = true;
	s->now = (struct time_slew_segment){mono_us, current, rate_ppb, slew};
}
```

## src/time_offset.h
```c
/* SPDX-License-Identifier: Apache-2.0 */
#ifndef TIME_OFFSET_H_
#define TIME_OFFSET_H_

#include <stdbool.h>
#include <stdint.h>

/* Estimates server time from the board's monotonic clock using repeated
 * request/response exchanges (NTP style).
 *
 * One exchange gives offset = server - board, wrong by up to half its round
 * trip when the two directions differ. The exchange with the shortest round
 * trip among the last TIME_OFFSET_WINDOW is therefore used as the estimate.
 * The rate between the clocks comes from the best exchanges of successive
 * windows. Nothing here can detect a constant asymmetry of the path.
 */
#define TIME_OFFSET_WINDOW  8
#define TIME_OFFSET_ANCHORS 6
/* Rate is only trusted over at least this span, and only within this bound;
 * crystal oscillators differ by tens of ppm. */
#define TIME_OFFSET_MIN_RATE_SPAN_US 30000000LL
#define TIME_OFFSET_MAX_RATE_PPB     500000LL

struct time_offset_sample {
	int64_t mono_us;   /* board monotonic time of the exchange */
	int64_t offset_us; /* server time minus board monotonic time */
	uint32_t delay_us; /* round trip without the server's processing time */
};

struct time_offset {
	struct time_offset_sample window[TIME_OFFSET_WINDOW];
	struct time_offset_sample anchors[TIME_OFFSET_ANCHORS];
	unsigned int count, next, anchor_count, since_anchor;
	int64_t rate_ppb; /* change of offset per second of board time */
	bool rate_valid;
	/* Diagnostics. */
	uint32_t samples, min_delay_us, last_delay_us;
	int64_t last_residual_us; /* newest offset minus the estimate before it */
};

void time_offset_init(struct time_offset *t);
void time_offset_add(struct time_offset *t, const struct time_offset_sample *sample);
/* Returns false until an exchange has been added. *delay_us is the round
 * trip of the exchange the estimate is based on; half of it bounds the error
 * from path asymmetry at that moment. */
bool time_offset_get(const struct time_offset *t, int64_t mono_us, int64_t *server_us,
		     uint32_t *delay_us);

/* A clock that follows the estimate without ever going backwards.
 *
 * The estimate jumps by a few milliseconds, in either direction, whenever it
 * switches to another exchange. This clock removes the difference gradually
 * instead: its speed differs from the board clock by the estimated rate plus
 * at most TIME_SLEW_MAX_PPB, so it is continuous and strictly increasing.
 * Only a difference of TIME_SLEW_STEP_US or more (first use, a stepped
 * server) is applied at once, and that is counted in `steps`.
 */
#define TIME_SLEW_MAX_PPB 500000LL
#define TIME_SLEW_SPAN_US 8000000LL
#define TIME_SLEW_STEP_US 500000LL

struct time_slew_segment {
	int64_t ref_mono_us, ref_time_us;
	int64_t rate_ppb, slew_ppb;
};

struct time_slew {
	bool valid, previous_valid;
	struct time_slew_segment now, previous;
	uint32_t steps;
};

void time_slew_init(struct time_slew *s);
/* target_us is the estimate for mono_us, rate_ppb its rate (0 if unknown). */
void time_slew_update(struct time_slew *s, int64_t mono_us, int64_t target_us, int64_t rate_ppb);
/* Events are converted a little after they happen, so times back to the
 * update before the last one are answered (false if earlier, or across a
 * step). The clock is continuous over both segments. */
bool time_slew_get(const struct time_slew *s, int64_t mono_us, int64_t *time_us);
#endif
```
